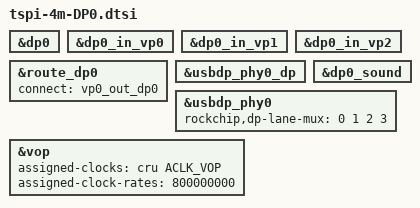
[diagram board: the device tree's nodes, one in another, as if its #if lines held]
/*
	Enable VOP0 and VOP1 for 8K DP. Other devices must not use these nodes.
	Define TSPI_DP_TX0_8K for 8K output. Disable the other display macros.
*/



// #define TSPI_DP_TX0_8K

/******************** DP TX0 ********************/
&dp0 {
	status = "disabled";
};

&dp0_in_vp0 {
	status = "disabled";
};

&dp0_in_vp1 {
	status = "disabled";
};

&dp0_in_vp2 {
	status = "disabled";
};

&route_dp0 {
	status = "disabled";
};

&usbdp_phy0_dp { 
	status = "disabled";
};

&dp0_sound { 
	status = "disabled";
};





#if defined(TSPI_DP_TX0)
&dp0 {
	status = "okay";
};

&dp0_in_vp2 {
	status = "okay";
};

&route_dp0 {
	status = "okay";
	connect = <&vp2_out_dp0>;
};

&usbdp_phy0 {
	rockchip,dp-lane-mux = <0 1 2 3>;
};

&usbdp_phy0_dp {
	status = "okay";
};

&dp0_sound {
	status = "okay";
};
#endif



#if defined(TSPI_DP_TX0_8K)
&dp0 {
	status = "okay";
};

&dp0_in_vp0 {
	status = "okay";
};

&dp0_in_vp1 {
	status = "okay";
};

&route_dp0 {
	status = "okay";
	connect = <&vp0_out_dp0>;
};

&usbdp_phy0 {
	rockchip,dp-lane-mux = <0 1 2 3>;
};

&usbdp_phy0_dp {
	status = "okay";
};

&dp0_sound {
	status = "okay";
};

&vop {
	status = "okay";
	assigned-clocks = <&cru ACLK_VOP>;
	assigned-clock-rates = <800000000>;
};
#endif
